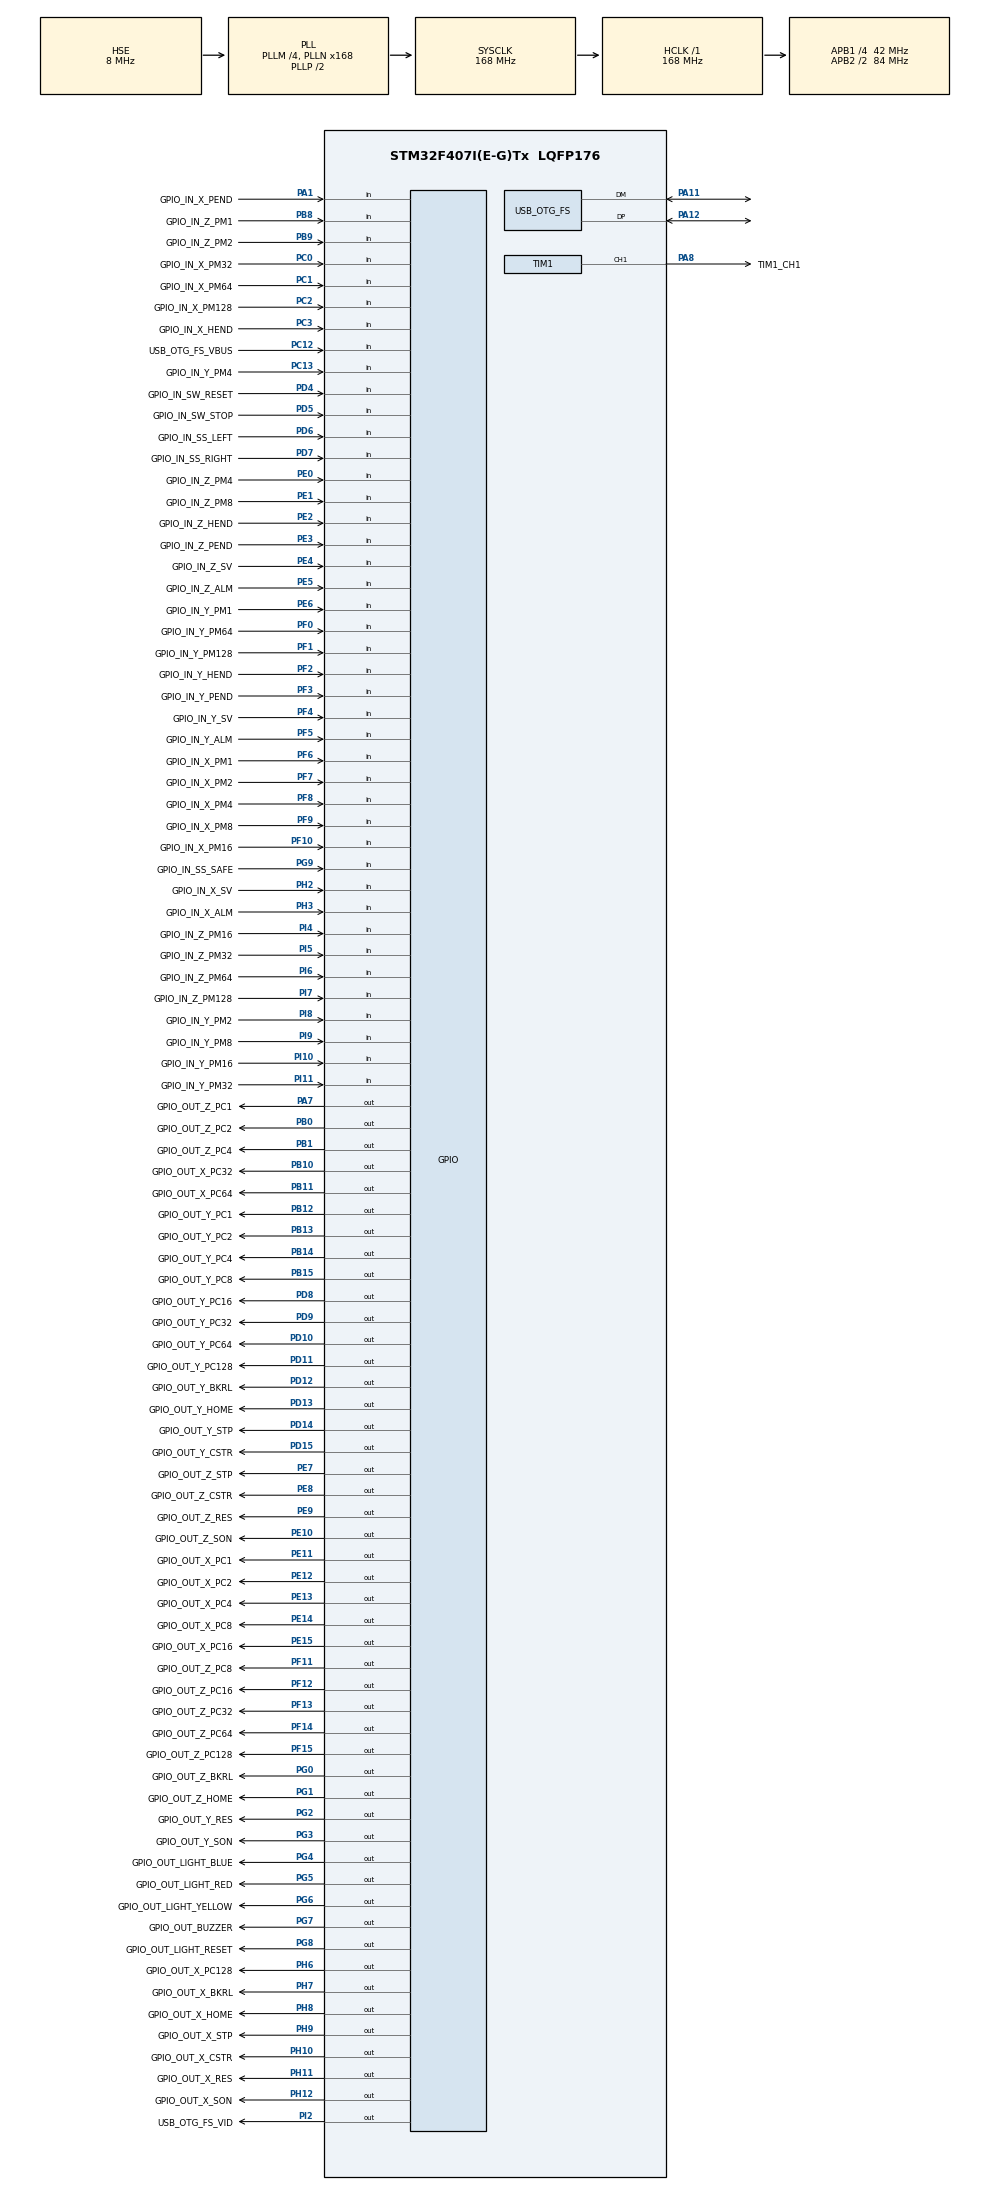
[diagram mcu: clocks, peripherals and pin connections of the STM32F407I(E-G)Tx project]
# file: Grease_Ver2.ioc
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FREERTOS.Tasks01=mTaskFlow,24,128,StartTaskFlow,Default,NULL,Dynamic,NULL,NULL;mTaskGPIO,8,128,StartTaskGPIO,Default,NULL,Dynamic,NULL,NULL;mTaskIAIX,8,128,StartTaskIAIX,Default,NULL,Dynamic,NULL,NULL;myTaskCOM,8,128,StartTaskCOM,Default,NULL,Dynamic,NULL,NULL;mTaskIAIY,8,128,StartTaskIAIY,Default,NULL,Dynamic,NULL,NULL;mTaskIAIZ,8,128,StartTaskIAIZ,Default,NULL,Dynamic,NULL,NULL;mTaskIAI,8,128,StartTaskIAI,Default,NULL,Dynamic,NULL,NULL
Mcu.Family=STM32F4
Mcu.Name=STM32F407I(E-G)Tx
Mcu.Package=LQFP176
NVIC.OTG_FS_IRQn=true\:5\:0\:false\:false\:true\:true\:false\:true\:true
NVIC.PriorityGroup=NVIC_PRIORITYGROUP_4
NVIC.TIM4_IRQn=true\:5\:0\:false\:false\:true\:true\:true\:true\:true
NVIC.TIM7_IRQn=true\:5\:0\:false\:false\:true\:true\:true\:true\:true
PA1.GPIO_Label=GPIO_IN_X_PEND
PA1.GPIO_PuPd=GPIO_PULLUP
PA1.Signal=GPIO_Input
PA11.Mode=Device_Only
PA11.Signal=USB_OTG_FS_DM
PA12.Mode=Device_Only
PA12.Signal=USB_OTG_FS_DP
PA13.Mode=Serial_Wire
PA13.Signal=SYS_JTMS-SWDIO
PA14.Mode=Serial_Wire
PA14.Signal=SYS_JTCK-SWCLK
PA7.GPIO_Label=GPIO_OUT_Z_PC1
PA7.GPIO_PuPd=GPIO_PULLDOWN
PA7.GPIO_Speed=GPIO_SPEED_FREQ_MEDIUM
PA7.Signal=GPIO_Output
PA8.GPIO_Label=TIM1_CH1
PA8.Signal=S_TIM1_CH1
PB0.GPIO_Label=GPIO_OUT_Z_PC2
PB0.GPIO_PuPd=GPIO_PULLDOWN
PB0.GPIO_Speed=GPIO_SPEED_FREQ_MEDIUM
PB0.Signal=GPIO_Output
PB1.GPIO_Label=GPIO_OUT_Z_PC4
PB1.GPIO_PuPd=GPIO_PULLDOWN
PB1.GPIO_Speed=GPIO_SPEED_FREQ_MEDIUM
PB1.Signal=GPIO_Output
PB10.GPIO_Label=GPIO_OUT_X_PC32
PB10.GPIO_PuPd=GPIO_PULLDOWN
PB10.GPIO_Speed=GPIO_SPEED_FREQ_MEDIUM
PB10.Signal=GPIO_Output
PB11.GPIO_Label=GPIO_OUT_X_PC64
PB11.GPIO_PuPd=GPIO_PULLDOWN
PB11.GPIO_Speed=GPIO_SPEED_FREQ_MEDIUM
PB11.Signal=GPIO_Output
PB12.GPIO_Label=GPIO_OUT_Y_PC1
PB12.GPIO_PuPd=GPIO_PULLDOWN
PB12.GPIO_Speed=GPIO_SPEED_FREQ_MEDIUM
PB12.Signal=GPIO_Output
PB13.GPIO_Label=GPIO_OUT_Y_PC2
PB13.GPIO_PuPd=GPIO_PULLDOWN
PB13.GPIO_Speed=GPIO_SPEED_FREQ_MEDIUM
PB13.Signal=GPIO_Output
PB14.GPIO_Label=GPIO_OUT_Y_PC4
PB14.GPIO_PuPd=GPIO_PULLDOWN
PB14.GPIO_Speed=GPIO_SPEED_FREQ_MEDIUM
PB14.Signal=GPIO_Output
PB15.GPIO_Label=GPIO_OUT_Y_PC8
PB15.GPIO_PuPd=GPIO_PULLDOWN
PB15.GPIO_Speed=GPIO_SPEED_FREQ_MEDIUM
PB15.Signal=GPIO_Output
PB8.GPIO_Label=GPIO_IN_Z_PM1
PB8.GPIO_PuPd=GPIO_PULLUP
PB8.Signal=GPIO_Input
PB9.GPIO_Label=GPIO_IN_Z_PM2
PB9.GPIO_PuPd=GPIO_PULLUP
PB9.Signal=GPIO_Input
PC0.GPIO_Label=GPIO_IN_X_PM32
PC0.GPIO_PuPd=GPIO_PULLUP
PC0.Signal=GPIO_Input
PC1.GPIO_Label=GPIO_IN_X_PM64
PC1.GPIO_PuPd=GPIO_PULLUP
PC1.Signal=GPIO_Input
PC12.GPIO_Label=USB_OTG_FS_VBUS
PC12.GPIO_PuPd=GPIO_PULLUP
PC12.Signal=GPIO_Input
PC13-ANTI_TAMP.GPIO_Label=GPIO_IN_Y_PM4
PC13-ANTI_TAMP.GPIO_PuPd=GPIO_PULLUP
PC13-ANTI_TAMP.Signal=GPIO_Input
PC2.GPIO_Label=GPIO_IN_X_PM128
PC2.GPIO_PuPd=GPIO_PULLUP
PC2.Signal=GPIO_Input
PC3.GPIO_Label=GPIO_IN_X_HEND
PC3.GPIO_PuPd=GPIO_PULLUP
PC3.Signal=GPIO_Input
PD10.GPIO_Label=GPIO_OUT_Y_PC64
PD10.GPIO_PuPd=GPIO_PULLDOWN
PD10.GPIO_Speed=GPIO_SPEED_FREQ_MEDIUM
PD10.Signal=GPIO_Output
PD11.GPIO_Label=GPIO_OUT_Y_PC128
PD11.GPIO_PuPd=GPIO_PULLDOWN
PD11.GPIO_Speed=GPIO_SPEED_FREQ_MEDIUM
PD11.Signal=GPIO_Output
PD12.GPIO_Label=GPIO_OUT_Y_BKRL
PD12.GPIO_PuPd=GPIO_PULLDOWN
PD12.GPIO_Speed=GPIO_SPEED_FREQ_MEDIUM
PD12.Signal=GPIO_Output
PD13.GPIO_Label=GPIO_OUT_Y_HOME
PD13.GPIO_PuPd=GPIO_PULLDOWN
PD13.GPIO_Speed=GPIO_SPEED_FREQ_MEDIUM
PD13.Signal=GPIO_Output
PD14.GPIO_Label=GPIO_OUT_Y_STP
PD14.GPIO_PuPd=GPIO_PULLDOWN
PD14.GPIO_Speed=GPIO_SPEED_FREQ_MEDIUM
PD14.Signal=GPIO_Output
PD15.GPIO_Label=GPIO_OUT_Y_CSTR
PD15.GPIO_PuPd=GPIO_PULLDOWN
PD15.GPIO_Speed=GPIO_SPEED_FREQ_MEDIUM
PD15.Signal=GPIO_Output
PD4.GPIO_Label=GPIO_IN_SW_RESET
PD4.GPIO_PuPd=GPIO_PULLUP
PD4.Signal=GPIO_Input
PD5.GPIO_Label=GPIO_IN_SW_STOP
PD5.GPIO_PuPd=GPIO_PULLUP
PD5.Signal=GPIO_Input
PD6.GPIO_Label=GPIO_IN_SS_LEFT
PD6.GPIO_PuPd=GPIO_PULLUP
PD6.Signal=GPIO_Input
PD7.GPIO_Label=GPIO_IN_SS_RIGHT
PD7.GPIO_PuPd=GPIO_PULLUP
PD7.Signal=GPIO_Input
PD8.GPIO_Label=GPIO_OUT_Y_PC16
PD8.GPIO_PuPd=GPIO_PULLDOWN
PD8.GPIO_Speed=GPIO_SPEED_FREQ_MEDIUM
PD8.Signal=GPIO_Output
PD9.GPIO_Label=GPIO_OUT_Y_PC32
PD9.GPIO_PuPd=GPIO_PULLDOWN
PD9.GPIO_Speed=GPIO_SPEED_FREQ_MEDIUM
PD9.Signal=GPIO_Output
PE0.GPIO_Label=GPIO_IN_Z_PM4
PE0.GPIO_PuPd=GPIO_PULLUP
PE0.Signal=GPIO_Input
PE1.GPIO_Label=GPIO_IN_Z_PM8
PE1.GPIO_PuPd=GPIO_PULLUP
PE1.Signal=GPIO_Input
PE10.GPIO_Label=GPIO_OUT_Z_SON
PE10.GPIO_PuPd=GPIO_PULLDOWN
PE10.GPIO_Speed=GPIO_SPEED_FREQ_MEDIUM
PE10.Signal=GPIO_Output
PE11.GPIO_Label=GPIO_OUT_X_PC1
PE11.GPIO_PuPd=GPIO_PULLDOWN
PE11.GPIO_Speed=GPIO_SPEED_FREQ_MEDIUM
PE11.Signal=GPIO_Output
PE12.GPIO_Label=GPIO_OUT_X_PC2
PE12.GPIO_PuPd=GPIO_PULLDOWN
PE12.GPIO_Speed=GPIO_SPEED_FREQ_MEDIUM
PE12.Signal=GPIO_Output
PE13.GPIO_Label=GPIO_OUT_X_PC4
PE13.GPIO_PuPd=GPIO_PULLDOWN
PE13.GPIO_Speed=GPIO_SPEED_FREQ_MEDIUM
PE13.Signal=GPIO_Output
PE14.GPIO_Label=GPIO_OUT_X_PC8
PE14.GPIO_PuPd=GPIO_PULLDOWN
PE14.GPIO_Speed=GPIO_SPEED_FREQ_MEDIUM
PE14.Signal=GPIO_Output
PE15.GPIO_Label=GPIO_OUT_X_PC16
PE15.GPIO_PuPd=GPIO_PULLDOWN
PE15.GPIO_Speed=GPIO_SPEED_FREQ_MEDIUM
PE15.Signal=GPIO_Output
PE2.GPIO_Label=GPIO_IN_Z_HEND
PE2.GPIO_PuPd=GPIO_PULLUP
PE2.Signal=GPIO_Input
PE3.GPIO_Label=GPIO_IN_Z_PEND
PE3.GPIO_PuPd=GPIO_PULLUP
PE3.Signal=GPIO_Input
PE4.GPIO_Label=GPIO_IN_Z_SV
PE4.GPIO_PuPd=GPIO_PULLUP
PE4.Signal=GPIO_Input
PE5.GPIO_Label=GPIO_IN_Z_ALM
PE5.GPIO_PuPd=GPIO_PULLUP
PE5.Signal=GPIO_Input
PE6.GPIO_Label=GPIO_IN_Y_PM1
PE6.GPIO_PuPd=GPIO_PULLUP
PE6.Signal=GPIO_Input
PE7.GPIO_Label=GPIO_OUT_Z_STP
PE7.GPIO_PuPd=GPIO_PULLDOWN
PE7.GPIO_Speed=GPIO_SPEED_FREQ_MEDIUM
PE7.Signal=GPIO_Output
PE8.GPIO_Label=GPIO_OUT_Z_CSTR
PE8.GPIO_PuPd=GPIO_PULLDOWN
PE8.GPIO_Speed=GPIO_SPEED_FREQ_MEDIUM
PE8.Signal=GPIO_Output
PE9.GPIO_Label=GPIO_OUT_Z_RES
PE9.GPIO_PuPd=GPIO_PULLDOWN
PE9.GPIO_Speed=GPIO_SPEED_FREQ_MEDIUM
PE9.Signal=GPIO_Output
PF0.GPIO_Label=GPIO_IN_Y_PM64
PF0.GPIO_PuPd=GPIO_PULLUP
PF0.Signal=GPIO_Input
PF1.GPIO_Label=GPIO_IN_Y_PM128
PF1.GPIO_PuPd=GPIO_PULLUP
PF1.Signal=GPIO_Input
PF10.GPIO_Label=GPIO_IN_X_PM16
PF10.GPIO_PuPd=GPIO_PULLUP
PF10.Signal=GPIO_Input
PF11.GPIO_Label=GPIO_OUT_Z_PC8
PF11.GPIO_PuPd=GPIO_PULLDOWN
PF11.GPIO_Speed=GPIO_SPEED_FREQ_MEDIUM
PF11.Signal=GPIO_Output
PF12.GPIO_Label=GPIO_OUT_Z_PC16
PF12.GPIO_PuPd=GPIO_PULLDOWN
PF12.GPIO_Speed=GPIO_SPEED_FREQ_MEDIUM
PF12.Signal=GPIO_Output
PF13.GPIO_Label=GPIO_OUT_Z_PC32
PF13.GPIO_PuPd=GPIO_PULLDOWN
PF13.GPIO_Speed=GPIO_SPEED_FREQ_MEDIUM
PF13.Signal=GPIO_Output
PF14.GPIO_Label=GPIO_OUT_Z_PC64
PF14.GPIO_PuPd=GPIO_PULLDOWN
PF14.GPIO_Speed=GPIO_SPEED_FREQ_MEDIUM
PF14.Signal=GPIO_Output
PF15.GPIO_Label=GPIO_OUT_Z_PC128
PF15.GPIO_PuPd=GPIO_PULLDOWN
PF15.GPIO_Speed=GPIO_SPEED_FREQ_MEDIUM
PF15.Signal=GPIO_Output
PF2.GPIO_Label=GPIO_IN_Y_HEND
PF2.GPIO_PuPd=GPIO_PULLUP
PF2.Signal=GPIO_Input
PF3.GPIO_Label=GPIO_IN_Y_PEND
PF3.GPIO_PuPd=GPIO_PULLUP
PF3.Signal=GPIO_Input
PF4.GPIO_Label=GPIO_IN_Y_SV
PF4.GPIO_PuPd=GPIO_PULLUP
PF4.Signal=GPIO_Input
PF5.GPIO_Label=GPIO_IN_Y_ALM
PF5.GPIO_PuPd=GPIO_PULLUP
PF5.Signal=GPIO_Input
PF6.GPIO_Label=GPIO_IN_X_PM1
PF6.GPIO_PuPd=GPIO_PULLUP
PF6.Signal=GPIO_Input
PF7.GPIO_Label=GPIO_IN_X_PM2
PF7.GPIO_PuPd=GPIO_PULLUP
PF7.Signal=GPIO_Input
PF8.GPIO_Label=GPIO_IN_X_PM4
PF8.GPIO_PuPd=GPIO_PULLUP
PF8.Signal=GPIO_Input
PF9.GPIO_Label=GPIO_IN_X_PM8
PF9.GPIO_PuPd=GPIO_PULLUP
PF9.Signal=GPIO_Input
PG0.GPIO_Label=GPIO_OUT_Z_BKRL
PG0.GPIO_PuPd=GPIO_PULLDOWN
PG0.GPIO_Speed=GPIO_SPEED_FREQ_MEDIUM
PG0.Signal=GPIO_Output
PG1.GPIO_Label=GPIO_OUT_Z_HOME
PG1.GPIO_PuPd=GPIO_PULLDOWN
PG1.GPIO_Speed=GPIO_SPEED_FREQ_MEDIUM
PG1.Signal=GPIO_Output
PG2.GPIO_Label=GPIO_OUT_Y_RES
PG2.GPIO_PuPd=GPIO_PULLDOWN
PG2.GPIO_Speed=GPIO_SPEED_FREQ_MEDIUM
PG2.Signal=GPIO_Output
PG3.GPIO_Label=GPIO_OUT_Y_SON
PG3.GPIO_PuPd=GPIO_PULLDOWN
PG3.GPIO_Speed=GPIO_SPEED_FREQ_MEDIUM
PG3.Signal=GPIO_Output
PG4.GPIO_Label=GPIO_OUT_LIGHT_BLUE
PG4.GPIO_PuPd=GPIO_PULLDOWN
PG4.GPIO_Speed=GPIO_SPEED_FREQ_LOW
PG4.Signal=GPIO_Output
PG5.GPIO_Label=GPIO_OUT_LIGHT_RED
PG5.GPIO_PuPd=GPIO_PULLDOWN
PG5.GPIO_Speed=GPIO_SPEED_FREQ_LOW
PG5.Signal=GPIO_Output
PG6.GPIO_Label=GPIO_OUT_LIGHT_YELLOW
PG6.GPIO_PuPd=GPIO_PULLDOWN
PG6.GPIO_Speed=GPIO_SPEED_FREQ_LOW
PG6.Signal=GPIO_Output
PG7.GPIO_Label=GPIO_OUT_BUZZER
PG7.GPIO_PuPd=GPIO_PULLDOWN
PG7.Signal=GPIO_Output
PG8.GPIO_Label=GPIO_OUT_LIGHT_RESET
PG8.GPIO_PuPd=GPIO_PULLDOWN
PG8.Signal=GPIO_Output
PG9.GPIO_Label=GPIO_IN_SS_SAFE
PG9.GPIO_PuPd=GPIO_PULLUP
PG9.Signal=GPIO_Input
PH0-OSC_IN.Mode=HSE-External-Oscillator
PH0-OSC_IN.Signal=RCC_OSC_IN
PH1-OSC_OUT.Mode=HSE-External-Oscillator
PH1-OSC_OUT.Signal=RCC_OSC_OUT
PH10.GPIO_Label=GPIO_OUT_X_CSTR
PH10.GPIO_PuPd=GPIO_PULLDOWN
PH10.GPIO_Speed=GPIO_SPEED_FREQ_MEDIUM
PH10.Signal=GPIO_Output
PH11.GPIO_Label=GPIO_OUT_X_RES
PH11.GPIO_PuPd=GPIO_PULLDOWN
PH11.GPIO_Speed=GPIO_SPEED_FREQ_MEDIUM
PH11.Signal=GPIO_Output
PH12.GPIO_Label=GPIO_OUT_X_SON
PH12.GPIO_PuPd=GPIO_PULLDOWN
PH12.GPIO_Speed=GPIO_SPEED_FREQ_MEDIUM
PH12.Signal=GPIO_Output
PH2.GPIO_Label=GPIO_IN_X_SV
PH2.GPIO_PuPd=GPIO_PULLUP
PH2.Signal=GPIO_Input
PH3.GPIO_Label=GPIO_IN_X_ALM
PH3.GPIO_PuPd=GPIO_PULLUP
PH3.Signal=GPIO_Input
PH6.GPIO_Label=GPIO_OUT_X_PC128
PH6.GPIO_PuPd=GPIO_PULLDOWN
PH6.GPIO_Speed=GPIO_SPEED_FREQ_MEDIUM
PH6.Signal=GPIO_Output
PH7.GPIO_Label=GPIO_OUT_X_BKRL
PH7.GPIO_PuPd=GPIO_PULLDOWN
PH7.GPIO_Speed=GPIO_SPEED_FREQ_MEDIUM
PH7.Signal=GPIO_Output
PH8.GPIO_Label=GPIO_OUT_X_HOME
PH8.GPIO_PuPd=GPIO_PULLDOWN
PH8.GPIO_Speed=GPIO_SPEED_FREQ_MEDIUM
PH8.Signal=GPIO_Output
PH9.GPIO_Label=GPIO_OUT_X_STP
PH9.GPIO_PuPd=GPIO_PULLDOWN
PH9.GPIO_Speed=GPIO_SPEED_FREQ_MEDIUM
PH9.Signal=GPIO_Output
PI10.GPIO_Label=GPIO_IN_Y_PM16
PI10.GPIO_PuPd=GPIO_PULLUP
PI10.Signal=GPIO_Input
PI11.GPIO_Label=GPIO_IN_Y_PM32
PI11.GPIO_PuPd=GPIO_PULLUP
PI11.Signal=GPIO_Input
PI2.GPIO_Label=USB_OTG_FS_VID
PI2.GPIO_PuPd=GPIO_PULLDOWN
PI2.Signal=GPIO_Output
PI4.GPIO_Label=GPIO_IN_Z_PM16
PI4.GPIO_PuPd=GPIO_PULLUP
PI4.Signal=GPIO_Input
PI5.GPIO_Label=GPIO_IN_Z_PM32
PI5.GPIO_PuPd=GPIO_PULLUP
PI5.Signal=GPIO_Input
PI6.GPIO_Label=GPIO_IN_Z_PM64
PI6.GPIO_PuPd=GPIO_PULLUP
PI6.Signal=GPIO_Input
PI7.GPIO_Label=GPIO_IN_Z_PM128
PI7.GPIO_PuPd=GPIO_PULLUP
PI7.Signal=GPIO_Input
PI8-\ ANTI\ TAMP2.GPIO_Label=GPIO_IN_Y_PM2
PI8-\ ANTI\ TAMP2.GPIO_PuPd=GPIO_PULLUP
PI8-\ ANTI\ TAMP2.Signal=GPIO_Input
PI9.GPIO_Label=GPIO_IN_Y_PM8
PI9.GPIO_PuPd=GPIO_PULLUP
PI9.Signal=GPIO_Input
ProjectManager.HeapSize=0x200
ProjectManager.StackSize=0x400
ProjectManager.TargetToolchain=STM32CubeIDE
RCC.48MHZClocksFreq_Value=48000000
RCC.AHBFreq_Value=168000000
RCC.APB1CLKDivider=RCC_HCLK_DIV4
RCC.APB1Freq_Value=42000000
RCC.APB1TimFreq_Value=84000000
RCC.APB2CLKDivider=RCC_HCLK_DIV2
RCC.APB2Freq_Value=84000000
RCC.APB2TimFreq_Value=168000000
RCC.CortexFreq_Value=168000000
RCC.HCLKFreq_Value=168000000
RCC.HSE_VALUE=8000000
RCC.HSI_VALUE=16000000
RCC.LSE_VALUE=32768
RCC.PLLM=4
RCC.PLLN=168
RCC.PLLQ=7
RCC.SYSCLKFreq_VALUE=168000000
RCC.SYSCLKSource=RCC_SYSCLKSOURCE_PLLCLK
RCC.VCOOutputFreq_Value=336000000
SH.S_TIM1_CH1.0=TIM1_CH1,PWM Generation1 CH1
TIM1.Channel-PWM\ Generation1\ CH1=TIM_CHANNEL_1
USB_DEVICE.CLASS_NAME_FS=CDC
USB_DEVICE.VirtualMode-CDC_FS=Cdc
USB_DEVICE.VirtualModeFS=Cdc_FS
USB_OTG_FS.VirtualMode=Device_Only
VP_FREERTOS_VS_CMSIS_V2.Mode=CMSIS_V2
VP_TIM1_VS_ClockSourceINT.Mode=Internal
VP_TIM4_VS_ClockSourceINT.Mode=Internal
VP_TIM7_VS_ClockSourceINT.Mode=Enable_Timer
VP_USB_DEVICE_VS_USB_DEVICE_CDC_FS.Mode=CDC_FS
board=custom

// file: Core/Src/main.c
/* USER CODE BEGIN Header */
/**
  ******************************************************************************
  * @file           : main.c
  * @brief          : Main program body
  ******************************************************************************
  * @attention
  *
  * Copyright (c) 2025 STMicroelectronics.
  * All rights reserved.
  *
  * This software is licensed under terms that can be found in the LICENSE file
  * in the root directory of this software component.
  * If no LICENSE file comes with this software, it is provided AS-IS.
  *
  ******************************************************************************
  */
/* USER CODE END Header */
#include "main.h"
#include "cmsis_os.h"
#include "usb_device.h"

/* USER CODE BEGIN Includes */
#include "mIAI.h"
#include "mVariable.h"
#include "mFunction.h"
#include "mFlow.h"
#include "mGPIO.h"
#include "mRS232.h"
#include "mErrorHandle.h"
/* USER CODE END Includes */

/* USER CODE BEGIN PD */
#define configUSE_TRACE_FACILITY 1
/* USER CODE END PD */

TIM_HandleTypeDef htim1;
TIM_HandleTypeDef htim4;
TIM_HandleTypeDef htim7;

/* Definitions for mTaskFlow */
osThreadId_t mTaskFlowHandle;
const osThreadAttr_t mTaskFlow_attributes = {
  .name = "mTaskFlow",
  .stack_size = 512 * 4,
  .priority = (osPriority_t) osPriorityNormal,
};
/* Definitions for mTaskGPIO */
osThreadId_t mTaskGPIOHandle;
const osThreadAttr_t mTaskGPIO_attributes = {
  .name = "mTaskGPIO",
  .stack_size = 256 * 4,
  .priority = (osPriority_t) osPriorityNormal,
};
/* Definitions for mTaskIAIX */
osThreadId_t mTaskIAIXHandle;
const osThreadAttr_t mTaskIAIX_attributes = {
  .name = "mTaskIAIX",
  .stack_size = 512 * 4,
  .priority = (osPriority_t) osPriorityNormal,
};
/* Definitions for myTaskCOM */
osThreadId_t myTaskCOMHandle;
const osThreadAttr_t myTaskCOM_attributes = {
  .name = "myTaskCOM",
  .stack_size = 512 * 4,
  .priority = (osPriority_t) osPriorityNormal,
};
/* Definitions for mTaskIAIY */
osThreadId_t mTaskIAIYHandle;
const osThreadAttr_t mTaskIAIY_attributes = {
  .name = "mTaskIAIY",
  .stack_size = 512 * 4,
  .priority = (osPriority_t) osPriorityNormal,
};
/* Definitions for mTaskIAIZ */
osThreadId_t mTaskIAIZHandle;
const osThreadAttr_t mTaskIAIZ_attributes = {
  .name = "mTaskIAIZ",
  .stack_size = 512 * 4,
  .priority = (osPriority_t) osPriorityNormal,
};
/* Definitions for mTaskIAI */
osThreadId_t mTaskIAIHandle;
const osThreadAttr_t mTaskIAI_attributes = {
  .name = "mTaskIAI",
  .stack_size = 512 * 4,
  .priority = (osPriority_t) osPriorityNormal,
};

void SystemClock_Config(void);
static void MX_GPIO_Init(void);
static void MX_TIM1_Init(void);
static void MX_TIM7_Init(void);
static void MX_TIM4_Init(void);
void StartTaskFlow(void *argument);
void StartTaskGPIO(void *argument);
void StartTaskIAIX(void *argument);
void StartTaskCOM(void *argument);
void StartTaskIAIY(void *argument);
void StartTaskIAIZ(void *argument);
void StartTaskIAI(void *argument);

int main(void)
{

  /* MCU Configuration--------------------------------------------------------*/

  /* Reset of all peripherals, Initializes the Flash interface and the Systick. */
  HAL_Init();

  /* Configure the system clock */
  SystemClock_Config();

  /* Initialize all configured peripherals */
  MX_GPIO_Init();
  MX_TIM1_Init();
  MX_TIM7_Init();
  MX_TIM4_Init();

  /* Init scheduler */
  osKernelInitialize();

  /* USER CODE BEGIN RTOS_TIMERS */
  /* start timers, add new ones, ... */
  MX_USB_DEVICE_Init();
  MX_TIM1_Init();
  MX_TIM4_Init();
  MX_TIM7_Init();
  HAL_TIM_PWM_Start(&htim1, TIM_CHANNEL_1);
  HAL_TIM_Base_Start(&htim4);
  HAL_TIM_Base_Start(&htim7);

  /* USER CODE END RTOS_TIMERS */

  /* USER CODE BEGIN RTOS_QUEUES */
  stepIAI = STEP_IAI_WAIT;
  machineMode = EQ_MODE_INIT;
  isStopIAI = true;
  HAL_GPIO_WritePin(USB_OTG_FS_VID_GPIO_Port, USB_OTG_FS_VID_Pin, GPIO_PIN_SET);
  vTaskDelay(pdMS_TO_TICKS(300));
  /* USER CODE END RTOS_QUEUES */

  /* Create the thread(s) */
  /* creation of mTaskFlow */
  mTaskFlowHandle = osThreadNew(StartTaskFlow, NULL, &mTaskFlow_attributes);

  /* creation of mTaskGPIO */
  mTaskGPIOHandle = osThreadNew(StartTaskGPIO, NULL, &mTaskGPIO_attributes);

  /* creation of mTaskIAIX */
  mTaskIAIXHandle = osThreadNew(StartTaskIAIX, NULL, &mTaskIAIX_attributes);

  /* creation of myTaskCOM */
  myTaskCOMHandle = osThreadNew(StartTaskCOM, NULL, &myTaskCOM_attributes);

  /* creation of mTaskIAIY */
  mTaskIAIYHandle = osThreadNew(StartTaskIAIY, NULL, &mTaskIAIY_attributes);

  /* creation of mTaskIAIZ */
  mTaskIAIZHandle = osThreadNew(StartTaskIAIZ, NULL, &mTaskIAIZ_attributes);

  /* creation of mTaskIAI */
  mTaskIAIHandle = osThreadNew(StartTaskIAI, NULL, &mTaskIAI_attributes);

  /* Start scheduler */
  osKernelStart();

  /* We should never get here as control is now taken by the scheduler */

  /* Infinite loop */
  while (1)
  {

  }
}

void SystemClock_Config(void)
{
  RCC_OscInitTypeDef RCC_OscInitStruct = {0};
  RCC_ClkInitTypeDef RCC_ClkInitStruct = {0};

  /** Configure the main internal regulator output voltage
  */
  __HAL_RCC_PWR_CLK_ENABLE();
  __HAL_PWR_VOLTAGESCALING_CONFIG(PWR_REGULATOR_VOLTAGE_SCALE1);

  /** Initializes the RCC Oscillators according to the specified parameters
  * in the RCC_OscInitTypeDef structure.
  */
  RCC_OscInitStruct.OscillatorType = RCC_OSCILLATORTYPE_HSE;
  RCC_OscInitStruct.HSEState = RCC_HSE_ON;
  RCC_OscInitStruct.PLL.PLLState = RCC_PLL_ON;
  RCC_OscInitStruct.PLL.PLLSource = RCC_PLLSOURCE_HSE;
  RCC_OscInitStruct.PLL.PLLM = 4;
  RCC_OscInitStruct.PLL.PLLN = 168;
  RCC_OscInitStruct.PLL.PLLP = RCC_PLLP_DIV2;
  RCC_OscInitStruct.PLL.PLLQ = 7;
  if (HAL_RCC_OscConfig(&RCC_OscInitStruct) != HAL_OK)
  {
    Error_Handler();
  }

  /** Initializes the CPU, AHB and APB buses clocks
  */
  RCC_ClkInitStruct.ClockType = RCC_CLOCKTYPE_HCLK|RCC_CLOCKTYPE_SYSCLK
                              |RCC_CLOCKTYPE_PCLK1|RCC_CLOCKTYPE_PCLK2;
  RCC_ClkInitStruct.SYSCLKSource = RCC_SYSCLKSOURCE_PLLCLK;
  RCC_ClkInitStruct.AHBCLKDivider = RCC_SYSCLK_DIV1;
  RCC_ClkInitStruct.APB1CLKDivider = RCC_HCLK_DIV4;
  RCC_ClkInitStruct.APB2CLKDivider = RCC_HCLK_DIV2;

  if (HAL_RCC_ClockConfig(&RCC_ClkInitStruct, FLASH_LATENCY_5) != HAL_OK)
  {
    Error_Handler();
  }
}

static void MX_TIM1_Init(void)
{

  TIM_ClockConfigTypeDef sClockSourceConfig = {0};
  TIM_MasterConfigTypeDef sMasterConfig = {0};
  TIM_OC_InitTypeDef sConfigOC = {0};
  TIM_BreakDeadTimeConfigTypeDef sBreakDeadTimeConfig = {0};

  htim1.Instance = TIM1;
  htim1.Init.Prescaler = 8;
  htim1.Init.CounterMode = TIM_COUNTERMODE_UP;
  htim1.Init.Period = 499;
  htim1.Init.ClockDivision = TIM_CLOCKDIVISION_DIV1;
  htim1.Init.RepetitionCounter = 0;
  htim1.Init.AutoReloadPreload = TIM_AUTORELOAD_PRELOAD_DISABLE;
  if (HAL_TIM_Base_Init(&htim1) != HAL_OK)
  {
    Error_Handler();
  }
  sClockSourceConfig.ClockSource = TIM_CLOCKSOURCE_INTERNAL;
  if (HAL_TIM_ConfigClockSource(&htim1, &sClockSourceConfig) != HAL_OK)
  {
    Error_Handler();
  }
  if (HAL_TIM_PWM_Init(&htim1) != HAL_OK)
  {
    Error_Handler();
  }
  sMasterConfig.MasterOutputTrigger = TIM_TRGO_RESET;
  sMasterConfig.MasterSlaveMode = TIM_MASTERSLAVEMODE_DISABLE;
  if (HAL_TIMEx_MasterConfigSynchronization(&htim1, &sMasterConfig) != HAL_OK)
  {
    Error_Handler();
  }
  sConfigOC.OCMode = TIM_OCMODE_PWM1;
  sConfigOC.Pulse = currentLightValue;
  sConfigOC.OCPolarity = TIM_OCPOLARITY_HIGH;
  sConfigOC.OCNPolarity = TIM_OCNPOLARITY_HIGH;
  sConfigOC.OCFastMode = TIM_OCFAST_DISABLE;
  sConfigOC.OCIdleState = TIM_OCIDLESTATE_RESET;
  sConfigOC.OCNIdleState = TIM_OCNIDLESTATE_RESET;
  if (HAL_TIM_PWM_ConfigChannel(&htim1, &sConfigOC, TIM_CHANNEL_1) != HAL_OK)
  {
    Error_Handler();
  }
  sBreakDeadTimeConfig.OffStateRunMode = TIM_OSSR_DISABLE;
  sBreakDeadTimeConfig.OffStateIDLEMode = TIM_OSSI_DISABLE;
  sBreakDeadTimeConfig.LockLevel = TIM_LOCKLEVEL_OFF;
  sBreakDeadTimeConfig.DeadTime = 0;
  sBreakDeadTimeConfig.BreakState = TIM_BREAK_DISABLE;
  sBreakDeadTimeConfig.BreakPolarity = TIM_BREAKPOLARITY_HIGH;
  sBreakDeadTimeConfig.AutomaticOutput = TIM_AUTOMATICOUTPUT_DISABLE;
  if (HAL_TIMEx_ConfigBreakDeadTime(&htim1, &sBreakDeadTimeConfig) != HAL_OK)
  {
    Error_Handler();
  }
  HAL_TIM_MspPostInit(&htim1);

}

static void MX_TIM4_Init(void)
{

  TIM_ClockConfigTypeDef sClockSourceConfig = {0};
  TIM_MasterConfigTypeDef sMasterConfig = {0};

  htim4.Instance = TIM4;
  htim4.Init.Prescaler = 0;
  htim4.Init.CounterMode = TIM_COUNTERMODE_UP;
  htim4.Init.Period = 65535;
  htim4.Init.ClockDivision = TIM_CLOCKDIVISION_DIV1;
  htim4.Init.AutoReloadPreload = TIM_AUTORELOAD_PRELOAD_DISABLE;
  if (HAL_TIM_Base_Init(&htim4) != HAL_OK)
  {
    Error_Handler();
  }
  sClockSourceConfig.ClockSource = TIM_CLOCKSOURCE_INTERNAL;
  if (HAL_TIM_ConfigClockSource(&htim4, &sClockSourceConfig) != HAL_OK)
  {
    Error_Handler();
  }
  sMasterConfig.MasterOutputTrigger = TIM_TRGO_RESET;
  sMasterConfig.MasterSlaveMode = TIM_MASTERSLAVEMODE_DISABLE;
  if (HAL_TIMEx_MasterConfigSynchronization(&htim4, &sMasterConfig) != HAL_OK)
  {
    Error_Handler();
  }

}

static void MX_TIM7_Init(void)
{

  TIM_MasterConfigTypeDef sMasterConfig = {0};

  htim7.Instance = TIM7;
  htim7.Init.Prescaler = 0;
  htim7.Init.CounterMode = TIM_COUNTERMODE_UP;
  htim7.Init.Period = 65535;
  htim7.Init.AutoReloadPreload = TIM_AUTORELOAD_PRELOAD_DISABLE;
  if (HAL_TIM_Base_Init(&htim7) != HAL_OK)
  {
    Error_Handler();
  }
  sMasterConfig.MasterOutputTrigger = TIM_TRGO_RESET;
  sMasterConfig.MasterSlaveMode = TIM_MASTERSLAVEMODE_DISABLE;
  if (HAL_TIMEx_MasterConfigSynchronization(&htim7, &sMasterConfig) != HAL_OK)
  {
    Error_Handler();
  }

}

static void MX_GPIO_Init(void)
{
  GPIO_InitTypeDef GPIO_InitStruct = {0};

  /* GPIO Ports Clock Enable */
  __HAL_RCC_GPIOE_CLK_ENABLE();
  __HAL_RCC_GPIOI_CLK_ENABLE();
  __HAL_RCC_GPIOC_CLK_ENABLE();
  __HAL_RCC_GPIOF_CLK_ENABLE();
  __HAL_RCC_GPIOH_CLK_ENABLE();
  __HAL_RCC_GPIOA_CLK_ENABLE();
  __HAL_RCC_GPIOB_CLK_ENABLE();
  __HAL_RCC_GPIOG_CLK_ENABLE();
  __HAL_RCC_GPIOD_CLK_ENABLE();

  /*Configure GPIO pin Output Level */
  HAL_GPIO_WritePin(GPIO_OUT_Z_PC1_GPIO_Port, GPIO_OUT_Z_PC1_Pin, GPIO_PIN_RESET);

  /*Configure GPIO pin Output Level */
  HAL_GPIO_WritePin(GPIOB, GPIO_OUT_Z_PC2_Pin|GPIO_OUT_Z_PC4_Pin|GPIO_OUT_X_PC32_Pin|GPIO_OUT_X_PC64_Pin
                          |GPIO_OUT_Y_PC1_Pin|GPIO_OUT_Y_PC2_Pin|GPIO_OUT_Y_PC4_Pin|GPIO_OUT_Y_PC8_Pin, GPIO_PIN_RESET);

  /*Configure GPIO pin Output Level */
  HAL_GPIO_WritePin(GPIOF, GPIO_OUT_Z_PC8_Pin|GPIO_OUT_Z_PC16_Pin|GPIO_OUT_Z_PC32_Pin|GPIO_OUT_Z_PC64_Pin
                          |GPIO_OUT_Z_PC128_Pin, GPIO_PIN_RESET);

  /*Configure GPIO pin Output Level */
  HAL_GPIO_WritePin(GPIOG, GPIO_OUT_Z_BKRL_Pin|GPIO_OUT_Z_HOME_Pin|GPIO_OUT_Y_RES_Pin|GPIO_OUT_Y_SON_Pin
                          |GPIO_OUT_LIGHT_BLUE_Pin|GPIO_OUT_LIGHT_RED_Pin|GPIO_OUT_LIGHT_YELLOW_Pin|GPIO_OUT_BUZZER_Pin
                          |GPIO_OUT_LIGHT_RESET_Pin , GPIO_PIN_RESET);

  /*Configure GPIO pin Output Level */
  HAL_GPIO_WritePin(GPIOE, GPIO_OUT_Z_STP_Pin|GPIO_OUT_Z_CSTR_Pin|GPIO_OUT_Z_RES_Pin|GPIO_OUT_Z_SON_Pin
                          |GPIO_OUT_X_PC1_Pin|GPIO_OUT_X_PC2_Pin|GPIO_OUT_X_PC4_Pin|GPIO_OUT_X_PC8_Pin
                          |GPIO_OUT_X_PC16_Pin, GPIO_PIN_RESET);

  /*Configure GPIO pin Output Level */
  HAL_GPIO_WritePin(GPIOH, GPIO_OUT_X_PC128_Pin|GPIO_OUT_X_BKRL_Pin|GPIO_OUT_X_HOME_Pin|GPIO_OUT_X_STP_Pin
                          |GPIO_OUT_X_CSTR_Pin|GPIO_OUT_X_RES_Pin|GPIO_OUT_X_SON_Pin, GPIO_PIN_RESET);

  /*Configure GPIO pin Output Level */
  HAL_GPIO_WritePin(GPIOD, GPIO_OUT_Y_PC16_Pin|GPIO_OUT_Y_PC32_Pin|GPIO_OUT_Y_PC64_Pin|GPIO_OUT_Y_PC128_Pin
                          |GPIO_OUT_Y_BKRL_Pin|GPIO_OUT_Y_HOME_Pin|GPIO_OUT_Y_STP_Pin|GPIO_OUT_Y_CSTR_Pin, GPIO_PIN_RESET);

  /*Configure GPIO pin Output Level */
  HAL_GPIO_WritePin(USB_OTG_FS_VID_GPIO_Port, USB_OTG_FS_VID_Pin, GPIO_PIN_RESET);

  /*Configure GPIO pins : GPIO_IN_Z_HEND_Pin GPIO_IN_Z_PEND_Pin GPIO_IN_Z_SV_Pin GPIO_IN_Z_ALM_Pin
                           GPIO_IN_Y_PM1_Pin GPIO_IN_Z_PM4_Pin GPIO_IN_Z_PM8_Pin */
  GPIO_InitStruct.Pin = GPIO_IN_Z_HEND_Pin|GPIO_IN_Z_PEND_Pin|GPIO_IN_Z_SV_Pin|GPIO_IN_Z_ALM_Pin
                          |GPIO_IN_Y_PM1_Pin|GPIO_IN_Z_PM4_Pin|GPIO_IN_Z_PM8_Pin;
  GPIO_InitStruct.Mode = GPIO_MODE_INPUT;
  GPIO_InitStruct.Pull = GPIO_PULLUP;
  HAL_GPIO_Init(GPIOE, &GPIO_InitStruct);

  /*Configure GPIO pins : GPIO_IN_Y_PM2_Pin GPIO_IN_Y_PM8_Pin GPIO_IN_Y_PM16_Pin GPIO_IN_Y_PM32_Pin
                           GPIO_IN_Z_PM16_Pin GPIO_IN_Z_PM32_Pin GPIO_IN_Z_PM64_Pin GPIO_IN_Z_PM128_Pin */
  GPIO_InitStruct.Pin = GPIO_IN_Y_PM2_Pin|GPIO_IN_Y_PM8_Pin|GPIO_IN_Y_PM16_Pin|GPIO_IN_Y_PM32_Pin
                          |GPIO_IN_Z_PM16_Pin|GPIO_IN_Z_PM32_Pin|GPIO_IN_Z_PM64_Pin|GPIO_IN_Z_PM128_Pin;
  GPIO_InitStruct.Mode = GPIO_MODE_INPUT;
  GPIO_InitStruct.Pull = GPIO_PULLUP;
  HAL_GPIO_Init(GPIOI, &GPIO_InitStruct);

  /*Configure GPIO pins : GPIO_IN_Y_PM4_Pin GPIO_IN_X_PM32_Pin GPIO_IN_X_PM64_Pin GPIO_IN_X_PM128_Pin
                           GPIO_IN_X_HEND_Pin USB_OTG_FS_VBUS_Pin */
  GPIO_InitStruct.Pin = GPIO_IN_Y_PM4_Pin|GPIO_IN_X_PM32_Pin|GPIO_IN_X_PM64_Pin|GPIO_IN_X_PM128_Pin
                          |GPIO_IN_X_HEND_Pin|USB_OTG_FS_VBUS_Pin;
  GPIO_InitStruct.Mode = GPIO_MODE_INPUT;
  GPIO_InitStruct.Pull = GPIO_PULLUP;
  HAL_GPIO_Init(GPIOC, &GPIO_InitStruct);

  /*Configure GPIO pins : GPIO_IN_Y_PM64_Pin GPIO_IN_Y_PM128_Pin GPIO_IN_Y_HEND_Pin GPIO_IN_Y_PEND_Pin
                           GPIO_IN_Y_SV_Pin GPIO_IN_Y_ALM_Pin GPIO_IN_X_PM1_Pin GPIO_IN_X_PM2_Pin
                           GPIO_IN_X_PM4_Pin GPIO_IN_X_PM8_Pin GPIO_IN_X_PM16_Pin */
  GPIO_InitStruct.Pin = GPIO_IN_Y_PM64_Pin|GPIO_IN_Y_PM128_Pin|GPIO_IN_Y_HEND_Pin|GPIO_IN_Y_PEND_Pin
                          |GPIO_IN_Y_SV_Pin|GPIO_IN_Y_ALM_Pin|GPIO_IN_X_PM1_Pin|GPIO_IN_X_PM2_Pin
                          |GPIO_IN_X_PM4_Pin|GPIO_IN_X_PM8_Pin|GPIO_IN_X_PM16_Pin;
  GPIO_InitStruct.Mode = GPIO_MODE_INPUT;
  GPIO_InitStruct.Pull = GPIO_PULLUP;
  HAL_GPIO_Init(GPIOF, &GPIO_InitStruct);

  /*Configure GPIO pin : GPIO_IN_X_PEND_Pin */
  GPIO_InitStruct.Pin = GPIO_IN_X_PEND_Pin;
  GPIO_InitStruct.Mode = GPIO_MODE_INPUT;
  GPIO_InitStruct.Pull = GPIO_PULLUP;
  HAL_GPIO_Init(GPIO_IN_X_PEND_GPIO_Port, &GPIO_InitStruct);

  /*Configure GPIO pins : GPIO_IN_X_SV_Pin GPIO_IN_X_ALM_Pin */
  GPIO_InitStruct.Pin = GPIO_IN_X_SV_Pin|GPIO_IN_X_ALM_Pin;
  GPIO_InitStruct.Mode = GPIO_MODE_INPUT;
  GPIO_InitStruct.Pull = GPIO_PULLUP;
  HAL_GPIO_Init(GPIOH, &GPIO_InitStruct);

  /*Configure GPIO pin : GPIO_OUT_Z_PC1_Pin */
  GPIO_InitStruct.Pin = GPIO_OUT_Z_PC1_Pin;
  GPIO_InitStruct.Mode = GPIO_MODE_OUTPUT_PP;
  GPIO_InitStruct.Pull = GPIO_PULLDOWN;
  GPIO_InitStruct.Speed = GPIO_SPEED_FREQ_MEDIUM;
  HAL_GPIO_Init(GPIO_OUT_Z_PC1_GPIO_Port, &GPIO_InitStruct);

  /*Configure GPIO pins : GPIO_OUT_Z_PC2_Pin GPIO_OUT_Z_PC4_Pin GPIO_OUT_X_PC32_Pin GPIO_OUT_X_PC64_Pin
                           GPIO_OUT_Y_PC1_Pin GPIO_OUT_Y_PC2_Pin GPIO_OUT_Y_PC4_Pin GPIO_OUT_Y_PC8_Pin */
  GPIO_InitStruct.Pin = GPIO_OUT_Z_PC2_Pin|GPIO_OUT_Z_PC4_Pin|GPIO_OUT_X_PC32_Pin|GPIO_OUT_X_PC64_Pin
                          |GPIO_OUT_Y_PC1_Pin|GPIO_OUT_Y_PC2_Pin|GPIO_OUT_Y_PC4_Pin|GPIO_OUT_Y_PC8_Pin;
  GPIO_InitStruct.Mode = GPIO_MODE_OUTPUT_PP;
  GPIO_InitStruct.Pull = GPIO_PULLDOWN;
  GPIO_InitStruct.Speed = GPIO_SPEED_FREQ_MEDIUM;
  HAL_GPIO_Init(GPIOB, &GPIO_InitStruct);

  /*Configure GPIO pins : GPIO_OUT_Z_PC8_Pin GPIO_OUT_Z_PC16_Pin GPIO_OUT_Z_PC32_Pin GPIO_OUT_Z_PC64_Pin
                           GPIO_OUT_Z_PC128_Pin */
  GPIO_InitStruct.Pin = GPIO_OUT_Z_PC8_Pin|GPIO_OUT_Z_PC16_Pin|GPIO_OUT_Z_PC32_Pin|GPIO_OUT_Z_PC64_Pin
                          |GPIO_OUT_Z_PC128_Pin;
  GPIO_InitStruct.Mode = GPIO_MODE_OUTPUT_PP;
  GPIO_InitStruct.Pull = GPIO_PULLDOWN;
  GPIO_InitStruct.Speed = GPIO_SPEED_FREQ_MEDIUM;
  HAL_GPIO_Init(GPIOF, &GPIO_InitStruct);

  /*Configure GPIO pins : GPIO_OUT_Z_BKRL_Pin GPIO_OUT_Z_HOME_Pin GPIO_OUT_Y_RES_Pin GPIO_OUT_Y_SON_Pin */
  GPIO_InitStruct.Pin = GPIO_OUT_Z_BKRL_Pin|GPIO_OUT_Z_HOME_Pin|GPIO_OUT_Y_RES_Pin|GPIO_OUT_Y_SON_Pin;
  GPIO_InitStruct.Mode = GPIO_MODE_OUTPUT_PP;
  GPIO_InitStruct.Pull = GPIO_PULLDOWN;
  GPIO_InitStruct.Speed = GPIO_SPEED_FREQ_MEDIUM;
  HAL_GPIO_Init(GPIOG, &GPIO_InitStruct);

  /*Configure GPIO pins : GPIO_OUT_Z_STP_Pin GPIO_OUT_Z_CSTR_Pin GPIO_OUT_Z_RES_Pin GPIO_OUT_Z_SON_Pin
                           GPIO_OUT_X_PC1_Pin GPIO_OUT_X_PC2_Pin GPIO_OUT_X_PC4_Pin GPIO_OUT_X_PC8_Pin
                           GPIO_OUT_X_PC16_Pin */
  GPIO_InitStruct.Pin = GPIO_OUT_Z_STP_Pin|GPIO_OUT_Z_CSTR_Pin|GPIO_OUT_Z_RES_Pin|GPIO_OUT_Z_SON_Pin
                          |GPIO_OUT_X_PC1_Pin|GPIO_OUT_X_PC2_Pin|GPIO_OUT_X_PC4_Pin|GPIO_OUT_X_PC8_Pin
                          |GPIO_OUT_X_PC16_Pin;
  GPIO_InitStruct.Mode = GPIO_MODE_OUTPUT_PP;
  GPIO_InitStruct.Pull = GPIO_PULLDOWN;
  GPIO_InitStruct.Speed = GPIO_SPEED_FREQ_MEDIUM;
  HAL_GPIO_Init(GPIOE, &GPIO_InitStruct);

  /*Configure GPIO pins : GPIO_OUT_X_PC128_Pin GPIO_OUT_X_BKRL_Pin GPIO_OUT_X_HOME_Pin GPIO_OUT_X_STP_Pin
                           GPIO_OUT_X_CSTR_Pin GPIO_OUT_X_RES_Pin GPIO_OUT_X_SON_Pin */
  GPIO_InitStruct.Pin = GPIO_OUT_X_PC128_Pin|GPIO_OUT_X_BKRL_Pin|GPIO_OUT_X_HOME_Pin|GPIO_OUT_X_STP_Pin
                          |GPIO_OUT_X_CSTR_Pin|GPIO_OUT_X_RES_Pin|GPIO_OUT_X_SON_Pin;
  GPIO_InitStruct.Mode = GPIO_MODE_OUTPUT_PP;
  GPIO_InitStruct.Pull = GPIO_PULLDOWN;
  GPIO_InitStruct.Speed = GPIO_SPEED_FREQ_MEDIUM;
  HAL_GPIO_Init(GPIOH, &GPIO_InitStruct);

  /*Configure GPIO pins : GPIO_OUT_Y_PC16_Pin GPIO_OUT_Y_PC32_Pin GPIO_OUT_Y_PC64_Pin GPIO_OUT_Y_PC128_Pin
                           GPIO_OUT_Y_BKRL_Pin GPIO_OUT_Y_HOME_Pin GPIO_OUT_Y_STP_Pin GPIO_OUT_Y_CSTR_Pin */
  GPIO_InitStruct.Pin = GPIO_OUT_Y_PC16_Pin|GPIO_OUT_Y_PC32_Pin|GPIO_OUT_Y_PC64_Pin|GPIO_OUT_Y_PC128_Pin
                          |GPIO_OUT_Y_BKRL_Pin|GPIO_OUT_Y_HOME_Pin|GPIO_OUT_Y_STP_Pin|GPIO_OUT_Y_CSTR_Pin;
  GPIO_InitStruct.Mode = GPIO_MODE_OUTPUT_PP;
  GPIO_InitStruct.Pull = GPIO_PULLDOWN;
  GPIO_InitStruct.Speed = GPIO_SPEED_FREQ_MEDIUM;
  HAL_GPIO_Init(GPIOD, &GPIO_InitStruct);

  /*Configure GPIO pins : GPIO_OUT_LIGHT_BLUE_Pin GPIO_OUT_LIGHT_RED_Pin GPIO_OUT_LIGHT_YELLOW_Pin GPIO_OUT_BUZZER_Pin
                           GPIO_OUT_LIGHT_RESET_Pin */
  GPIO_InitStruct.Pin = GPIO_OUT_LIGHT_BLUE_Pin|GPIO_OUT_LIGHT_RED_Pin|GPIO_OUT_LIGHT_YELLOW_Pin|GPIO_OUT_BUZZER_Pin
                          |GPIO_OUT_LIGHT_RESET_Pin;
  GPIO_InitStruct.Mode = GPIO_MODE_OUTPUT_PP;
  GPIO_InitStruct.Pull = GPIO_PULLDOWN;
  GPIO_InitStruct.Speed = GPIO_SPEED_FREQ_LOW;
  HAL_GPIO_Init(GPIOG, &GPIO_InitStruct);

  /*Configure GPIO pin : USB_OTG_FS_VID_Pin */
  GPIO_InitStruct.Pin = USB_OTG_FS_VID_Pin;
  GPIO_InitStruct.Mode = GPIO_MODE_OUTPUT_PP;
  GPIO_InitStruct.Pull = GPIO_PULLDOWN;
  GPIO_InitStruct.Speed = GPIO_SPEED_FREQ_LOW;
  HAL_GPIO_Init(USB_OTG_FS_VID_GPIO_Port, &GPIO_InitStruct);

  /*Configure GPIO pins : GPIO_IN_SW_RESET_Pin GPIO_IN_SW_STOP_Pin GPIO_IN_SS_LEFT_Pin GPIO_IN_SS_RIGHT_Pin */
  GPIO_InitStruct.Pin = GPIO_IN_SW_RESET_Pin|GPIO_IN_SW_STOP_Pin|GPIO_IN_SS_LEFT_Pin|GPIO_IN_SS_RIGHT_Pin;
  GPIO_InitStruct.Mode = GPIO_MODE_INPUT;
  GPIO_InitStruct.Pull = GPIO_PULLUP;
  HAL_GPIO_Init(GPIOD, &GPIO_InitStruct);

  /*Configure GPIO pin : GPIO_IN_SS_SAFE_Pin */
  GPIO_InitStruct.Pin = GPIO_IN_SS_SAFE_Pin | GPIO_IN_SW_START_Pin;
  GPIO_InitStruct.Mode = GPIO_MODE_INPUT;
  GPIO_InitStruct.Pull = GPIO_PULLUP;
  HAL_GPIO_Init(GPIOG, &GPIO_InitStruct);

  /*Configure GPIO pins : GPIO_IN_Z_PM1_Pin GPIO_IN_Z_PM2_Pin */
  GPIO_InitStruct.Pin = GPIO_IN_Z_PM1_Pin|GPIO_IN_Z_PM2_Pin;
  GPIO_InitStruct.Mode = GPIO_MODE_INPUT;
  GPIO_InitStruct.Pull = GPIO_PULLUP;
  HAL_GPIO_Init(GPIOB, &GPIO_InitStruct);

}

void StartTaskFlow(void *argument)
{
  /* init code for USB_DEVICE */
  MX_USB_DEVICE_Init();
  /* USER CODE BEGIN 5 */
  /* Infinite loop */
  for(;;)
  {
	eqHandleStatus();
	eqControl();
    osDelay(1);
  }
  /* USER CODE END 5 */
}

void StartTaskGPIO(void *argument)
{
  /* USER CODE BEGIN StartTaskGPIO */
  /* Infinite loop */
  for(;;)
  {
	gpioScan();

    osDelay(1);
  }
  /* USER CODE END StartTaskGPIO */
}

void StartTaskIAIX(void *argument)
{
  /* USER CODE BEGIN StartTaskIAIX */
  /* Infinite loop */
  for(;;)
  {
	if(axisX.request.REQ_PREPARE){
		axisX.prepare(&axisX);
	}else if(axisX.request.REQ_MOVE){
		axisX.move(&axisX,axisX.position.targetPos.toPos);
	}else if (axisX.request.REQ_ORG){
		axisX.home(&axisX);
	}else if(axisX.request.REQ_RESET){
		axisX.clearError(&axisX);
	}
    osDelay(1);
  }
  /* USER CODE END StartTaskIAIX */
}

void StartTaskCOM(void *argument)
{
  /* USER CODE BEGIN StartTaskCOM */
  /* Infinite loop */
  for(;;)
  {
	  //Z : Max 12
	  //X : Max 110
	  //Y : Max 75
	  getCmdHandle();
	  sendCmdHandle();
	  osDelay(30);

//	  char msg[512];
//	  int len = 0;
//
//	  len += snprintf(msg + len, sizeof(msg) - len, "IAIX Stack Free: %lu\n", uxTaskGetStackHighWaterMark(mTaskIAIXHandle));
//	  len += snprintf(msg + len, sizeof(msg) - len, "IAIY Stack Free: %lu\n", uxTaskGetStackHighWaterMark(mTaskIAIYHandle));
//	  len += snprintf(msg + len, sizeof(msg) - len, "IAIZ Stack Free: %lu\n", uxTaskGetStackHighWaterMark(mTaskIAIZHandle));
//	  len += snprintf(msg + len, sizeof(msg) - len, "IAI Stack Free: %lu\n",  uxTaskGetStackHighWaterMark(mTaskIAIHandle));
//	  len += snprintf(msg + len, sizeof(msg) - len, "COM Stack Free: %lu\n",  uxTaskGetStackHighWaterMark(myTaskCOMHandle));
//	  len += snprintf(msg + len, sizeof(msg) - len, "GPIO Stack Free: %lu\n", uxTaskGetStackHighWaterMark(mTaskGPIOHandle));
//	  len += snprintf(msg + len, sizeof(msg) - len, "FLOW Stack Free: %lu\n", uxTaskGetStackHighWaterMark(mTaskFlowHandle));
//
//	  CDC_Transmit_FS((uint8_t*)msg, len);
//	  osDelay(300);
   }
  /* USER CODE END StartTaskCOM */
}

void StartTaskIAIY(void *argument)
{
  /* USER CODE BEGIN StartTaskIAIY */
  /* Infinite loop */
  for(;;)
  {
	  if(axisY.request.REQ_PREPARE){
	  	axisY.prepare(&axisY);
	  }else if(axisY.request.REQ_MOVE){
	  	axisY.move(&axisY,axisY.position.targetPos.toPos);
	  }else if (axisY.request.REQ_ORG){
	  	axisY.home(&axisY);
	  }else if(axisY.request.REQ_RESET){
	  	axisY.clearError(&axisY);
	  }
    osDelay(1);

  }
  /* USER CODE END StartTaskIAIY */
}

void StartTaskIAIZ(void *argument)
{
  /* USER CODE BEGIN StartTaskIAIZ */
  /* Infinite loop */
  for(;;)
  {
	  if(axisZ.request.REQ_PREPARE){
	  	axisZ.prepare(&axisZ);
	  }else if(axisZ.request.REQ_MOVE){
	  	axisZ.move(&axisZ,axisZ.position.targetPos.toPos);
	  }else if (axisZ.request.REQ_ORG){
	  	axisZ.home(&axisZ);
	  }else if(axisZ.request.REQ_RESET){
	  	axisZ.clearError(&axisZ);
	  }
    osDelay(1);
  }
  /* USER CODE END StartTaskIAIZ */
}

void StartTaskIAI(void *argument)
{
  /* USER CODE BEGIN StartTaskIAI */
  /* Infinite loop */
  for(;;)
  {
	IAIMovingHandled();
	if(currentLightValue != targetLightValue){
		currentLightValue = targetLightValue;
		HAL_TIM_PWM_Stop(&htim1, TIM_CHANNEL_1);
		MX_TIM1_Init();
		HAL_TIM_PWM_Start(&htim1, TIM_CHANNEL_1);
	}
    osDelay(1);
  }
  /* USER CODE END StartTaskIAI */
}

void Error_Handler(void)
{
  __disable_irq();
  while (1)
  {
  }
}
